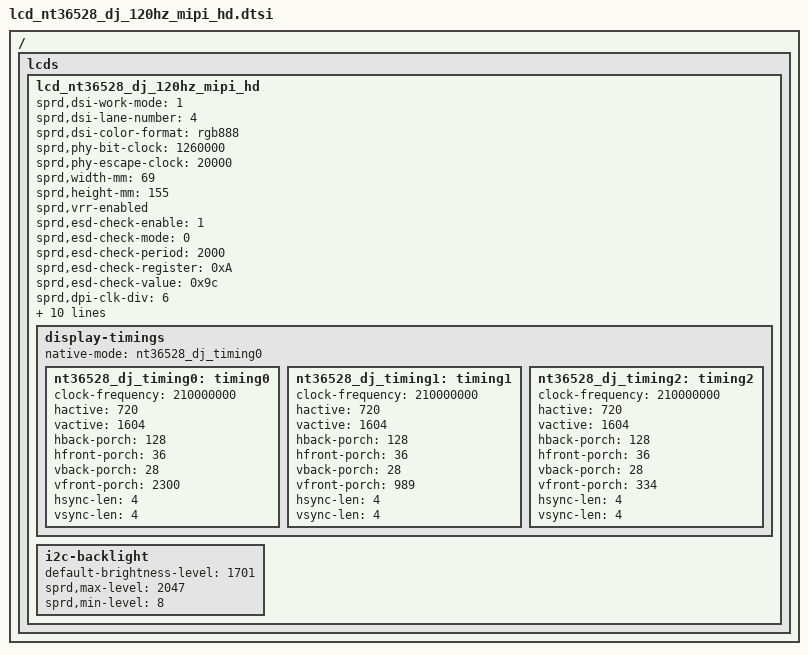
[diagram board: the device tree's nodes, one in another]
/ {
	fragment {
		target-path = "/";
		__overlay__ {
			lcds {
				lcd_nt36528_dj_120hz_mipi_hd: lcd_nt36528_dj_120hz_mipi_hd {

					sprd,dsi-work-mode = <1>; /* video burst mode*/
					sprd,dsi-lane-number = <4>;
					sprd,dsi-color-format = "rgb888";
					sprd,phy-bit-clock = <1260000>;
					sprd,phy-escape-clock = <20000>;/* kHz */
					sprd,width-mm = <69>;
					sprd,height-mm = <155>;
					sprd,vrr-enabled;
					sprd,esd-check-enable = <1>;
					sprd,esd-check-mode = <0>;
					sprd,esd-check-period = <2000>;
					sprd,esd-check-register = <0xA>;
					sprd,esd-check-value = <0x9c>;
					sprd,dpi-clk-div = <6>;
					sprd,video-lp-cmd-enable = <1>;
					sprd,hporch-lp-disable = <1>;

					sprd,reset-on-sequence = <0 5>, <1 10>, <0 5>, <1 15>;
					sprd,reset-off-sequence = <1 10>;

					sprd,initial-command = [
						15 00 00 02 FF 20
						15 00 00 02 FB 01
						15 00 00 02 05 AB
						15 00 00 02 07 DC
						15 00 00 02 08 78
						15 00 00 02 0D 80
						15 00 00 02 6D FF
						15 00 00 02 89 70
						15 00 00 02 94 00
						15 00 00 02 95 D7
						15 00 00 02 96 D7
						15 00 00 02 FF 23
						15 00 00 02 FB 01
						15 00 00 02 15 1D
						15 00 00 02 16 11
						15 00 00 02 FF 24
						15 00 00 02 FB 01
						15 00 00 02 00 00
						15 00 00 02 01 08
						15 00 00 02 02 09
						15 00 00 02 03 06
						15 00 00 02 04 00
						15 00 00 02 05 00
						15 00 00 02 06 00
						15 00 00 02 07 00
						15 00 00 02 08 00
						15 00 00 02 09 26
						15 00 00 02 0A 22
						15 00 00 02 0B 23
						15 00 00 02 0C 13
						15 00 00 02 0D 12
						15 00 00 02 0E 11
						15 00 00 02 0F 10
						15 00 00 02 10 0F
						15 00 00 02 11 0E
						15 00 00 02 12 0D
						15 00 00 02 13 0C
						15 00 00 02 14 05
						15 00 00 02 15 04
						15 00 00 02 16 00
						15 00 00 02 17 08
						15 00 00 02 18 09
						15 00 00 02 19 06
						15 00 00 02 1A 00
						15 00 00 02 1B 00
						15 00 00 02 1C 00
						15 00 00 02 1D 00
						15 00 00 02 1E 00
						15 00 00 02 1F 26
						15 00 00 02 20 22
						15 00 00 02 21 23
						15 00 00 02 22 13
						15 00 00 02 23 12
						15 00 00 02 24 11
						15 00 00 02 25 10
						15 00 00 02 26 0F
						15 00 00 02 27 0E
						15 00 00 02 28 0D
						15 00 00 02 29 0C
						15 00 00 02 2A 05
						15 00 00 02 2B 04
						15 00 00 02 2F 0A
						15 00 00 02 30 06
						15 00 00 02 31 4C
						15 00 00 02 33 30
						15 00 00 02 34 32
						15 00 00 02 35 44
						15 00 00 02 37 AA
						15 00 00 02 38 A4
						15 00 00 02 3A 48
						15 00 00 02 3B 46
						15 00 00 02 3D 53
						15 00 00 02 3F 45
						15 00 00 02 40 47
						15 00 00 02 41 4C
						15 00 00 02 43 0E
						15 00 00 02 44 12
						15 00 00 02 45 44
						15 00 00 02 47 55
						15 00 00 02 4A 48
						15 00 00 02 4B 46
						15 00 00 02 4C 53
						15 00 00 02 50 87
						15 00 00 02 51 56
						15 00 00 02 52 34
						15 00 00 02 53 12
						15 00 00 02 54 78
						39 00 00 03 55 44 0C
						15 00 00 02 56 08
						15 00 00 02 59 50
						15 00 00 02 5A 48
						15 00 00 02 5B 46
						15 00 00 02 61 44
						15 00 00 02 92 60
						39 00 00 03 93 4E 01
						15 00 00 02 94 14
						15 00 00 02 AB 55
						15 00 00 02 AC A4
						15 00 00 02 DC 5C
						15 00 00 02 F7 AA
						15 00 00 02 F8 A4
						15 00 00 02 FF 25
						15 00 00 02 FB 01
						39 00 00 03 02 00 40
						15 00 00 02 13 01
						15 00 00 02 14 25
						15 00 00 02 C6 10
						15 00 00 02 FF 26
						15 00 00 02 FB 01
						15 00 00 02 00 80
						15 00 00 02 02 0D
						15 00 00 02 FF 27
						15 00 00 02 FB 01
						15 00 00 02 58 AC
						39 00 00 03 59 00 17
						39 00 00 03 5A 01 4D
						39 00 00 03 5D 00 02
						39 00 00 03 5E 01 32
						15 00 00 02 5F 02
						39 00 00 03 60 06 79
						15 00 00 02 C0 08
						15 00 00 02 E5 AF
						15 00 00 02 E9 02
						15 00 00 02 F0 77
						15 00 00 02 F4 00
						15 00 00 02 F5 77
						15 00 00 02 FF 2A
						15 00 00 02 FB 01
						15 00 00 02 23 08
						15 00 00 02 27 01
						15 00 00 02 28 4E
						15 00 00 02 29 01
						15 00 00 02 2A 4E
						15 00 00 02 2B 01
						15 00 00 02 2D 4E
						15 00 00 02 99 95
						15 00 00 02 9A 0B
						15 00 00 02 AD 3F
						15 00 00 02 AE AA
						15 00 00 02 AF 43
						15 00 00 02 B0 18
						15 00 00 02 B1 93
						15 00 00 02 B3 66
						15 00 00 02 FF 23
						15 00 00 02 FB 01
						15 00 00 02 00 60
						15 00 00 02 07 00
						15 00 00 02 09 AF
						15 00 00 02 FF 10
						15 00 00 02 FB 01
						39 00 00 03 51 07 FF
						15 00 00 02 53 2C
						15 00 00 02 55 00
						15 00 00 02 35 00
						39 00 00 03 3B 03 14
						15 00 00 02 FF 24
						15 00 00 02 FB 01
						15 00 00 02 94 20
						15 00 00 02 FF 25
						15 00 00 02 FB 01
						15 00 00 02 14 23
						15 00 00 02 FF 10
						15 00 00 02 FB 01
						39 00 00 03 3B 03 20
						05 78 00 01 11
						05 14 00 01 29
						];

					sprd,sleep-in-command = [
						05 14 00 01 28
						05 78 00 01 10
						];
					sprd,sleep-out-command = [
						05 78 00 01 11
						05 14 00 01 29
						];

					display-timings {
						native-mode = <&nt36528_dj_timing0>;
						nt36528_dj_timing0: timing0 {
							clock-frequency = <210000000>;
							hactive = <720>;
							vactive = <1604>;
							hback-porch = <128>;
							hfront-porch = <36>;
							vback-porch = <28>;
							vfront-porch = <2300>;
							hsync-len = <4>;
							vsync-len = <4>;
						};

						nt36528_dj_timing1: timing1 {
							clock-frequency = <210000000>;
							hactive = <720>;
							vactive = <1604>;
							hback-porch = <128>;
							hfront-porch = <36>;
							vback-porch = <28>;
							vfront-porch = <989>;
							hsync-len = <4>;
							vsync-len = <4>;
						};

						nt36528_dj_timing2: timing2 {
							clock-frequency = <210000000>;
							hactive = <720>;
							vactive = <1604>;
							hback-porch = <128>;
							hfront-porch = <36>;
							vback-porch = <28>;
							vfront-porch = <334>;
							hsync-len = <4>;
							vsync-len = <4>;
						};
					};
					i2c-backlight {
						default-brightness-level = <1701>;
						sprd,max-level = <2047>;
						sprd,min-level = <8>;
					};
				};
			};
		};
	};
};
